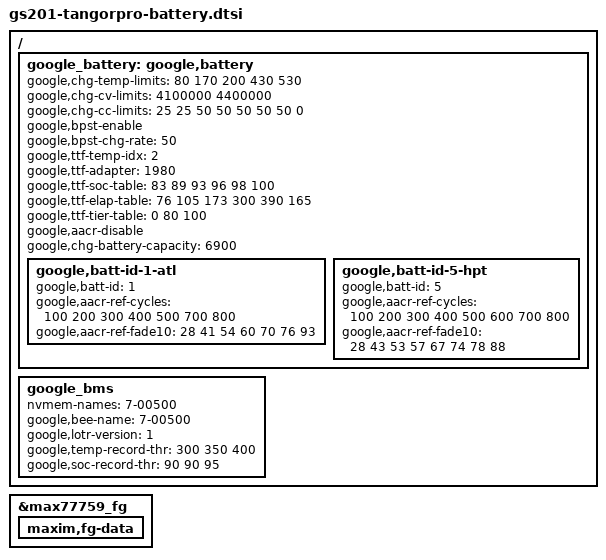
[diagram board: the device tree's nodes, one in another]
// SPDX-License-Identifier: GPL-2.0-only
/*
 * Battery device tree entries specific to tangorpro
 *
 * Copyright 2022 Google,LLC
 *
 */

&google_battery {
	google,chg-battery-capacity = <6900>;
};

&max77759_fg {
	/delete-property/ maxim,force-batt-id;
	maxim,fg-data {
		#include "gs201-tangorpro-battery-data.dtsi"
	};
};

/ {
	fragment@battery {
		target-path = "/";
		__overlay__ {
			google_battery: google,battery {
				/* charge table */
				google,chg-temp-limits = <80 170 200 430 530>;
				google,chg-cv-limits = <4100000 4400000>;
				google,chg-cc-limits = <
					25  25
					50  50
					50  50
					50   0
				>;

				/* bpst */
				google,bpst-enable;
				google,bpst-chg-rate = <50>;

				google,ttf-temp-idx= <2>;
				google,ttf-adapter = <1980>;
				google,ttf-soc-table =  <83 89  93  96  98  100>;
				google,ttf-elap-table = <76 105 173 300 390 165>;
				google,ttf-tier-table = <0 80 100>;

				google,aacr-disable;

				google,batt-id-1-atl {
					google,batt-id = <1>;
					google,aacr-ref-cycles = <100 200 300 400 500 700 800>;
					google,aacr-ref-fade10 = < 28  41  54  60  70  76  93>;
				};

				google,batt-id-5-hpt {
					google,batt-id = <5>;
					google,aacr-ref-cycles = <100 200 300 400 500 600 700 800>;
					google,aacr-ref-fade10 = < 28  43  53  57  67  74  78  88>;
				};
			};
			google_bms {
				nvmem-names = "7-00500";
				/* pack eeprom is available only with P20+ batteries */
				google,bee-name = "7-00500";

				/* eeprom layout tracker */
				google,lotr-version = <1>;

				/* record over temperature time */
				google,temp-record-thr = <300 350 400>;
				google,soc-record-thr = <90 90 95>;
			};
		};
	};
};
